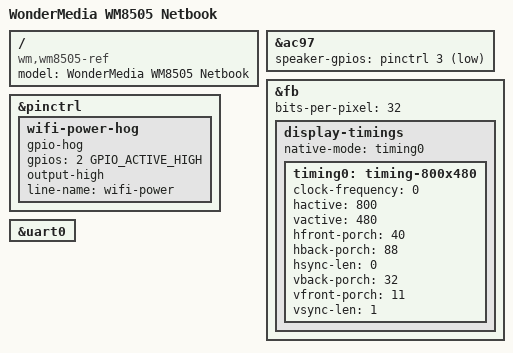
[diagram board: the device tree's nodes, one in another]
// SPDX-License-Identifier: GPL-2.0-or-later
/*
 * wm8505-ref.dts - Device tree file for WonderMedia WM8505 reference netbook
 *
 * Copyright (C) 2012 Tony Prisk <linux@prisktech.co.nz>
 * Copyright (C) 2026 Logan Russell <me@lrussell.net>
 */

/dts-v1/;

#include <dt-bindings/gpio/gpio.h>
#include "wm8505.dtsi"

/ {
	model = "WonderMedia WM8505 Netbook";
	compatible = "wm,wm8505-ref", "wm,wm8505";
};

&ac97 {
	speaker-gpios = <&pinctrl 3 GPIO_ACTIVE_LOW>;
	status = "okay";
};

&fb {
	bits-per-pixel = <32>;
	display-timings {
		native-mode = <&timing0>;
		timing0: timing-800x480 {
			clock-frequency = <0>; /* unused but required */
			hactive = <800>;
			vactive = <480>;
			hfront-porch = <40>;
			hback-porch = <88>;
			hsync-len = <0>;
			vback-porch = <32>;
			vfront-porch = <11>;
			vsync-len = <1>;
		};
	};
};

&pinctrl {
	wifi-power-hog {
		gpio-hog;
		gpios = <2 GPIO_ACTIVE_HIGH>;
		output-high;
		line-name = "wifi-power";
	};
};

&uart0 {
	status = "okay";
};
